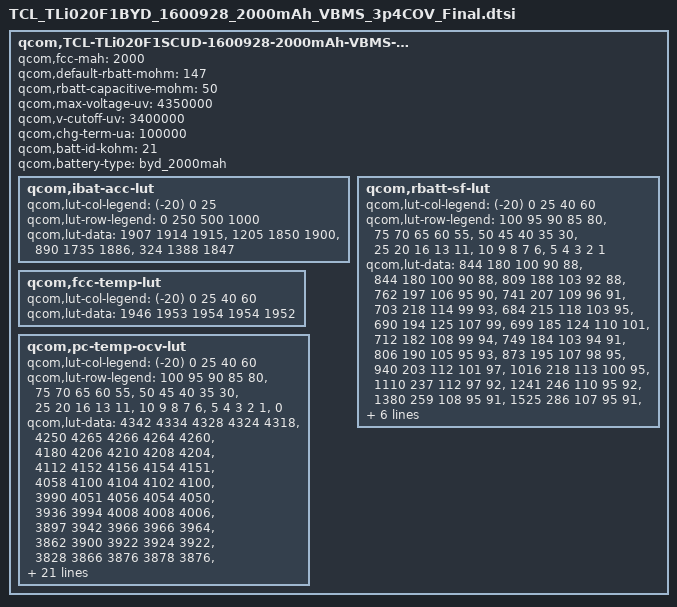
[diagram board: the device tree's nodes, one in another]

 qcom,TCL-TLi020F1SCUD-1600928-2000mAh-VBMS-data {
	qcom,fcc-mah = <2000>;
	qcom,default-rbatt-mohm = <147>;
	qcom,rbatt-capacitive-mohm = <50>;
	qcom,max-voltage-uv = <4350000>;
	qcom,v-cutoff-uv = <3400000>;
	qcom,chg-term-ua = <100000>;
	qcom,batt-id-kohm = <21>;
	qcom,battery-type = "byd_2000mah";
	qcom,ibat-acc-lut {
		qcom,lut-col-legend = <(-20) 0 25>;
		qcom,lut-row-legend = <0 250 500 1000>;
		qcom,lut-data = <1907 1914 1915>,
				<1205 1850 1900>,
				<890 1735 1886>,
				<324 1388 1847>;
	};

	qcom,rbatt-sf-lut {
		qcom,lut-col-legend = <(-20) 0 25 40 60>;
		qcom,lut-row-legend = <100 95 90 85 80>,
				<75 70 65 60 55>,
				<50 45 40 35 30>,
				<25 20 16 13 11>,
				<10 9 8 7 6>,
				<5 4 3 2 1>;
		qcom,lut-data = <844 180 100 90 88>,
				<844 180 100 90 88>,
				<809 188 103 92 88>,
				<762 197 106 95 90>,
				<741 207 109 96 91>,
				<703 218 114 99 93>,
				<684 215 118 103 95>,
				<690 194 125 107 99>,
				<699 185 124 110 101>,
				<712 182 108 99 94>,
				<749 184 103 94 91>,
				<806 190 105 95 93>,
				<873 195 107 98 95>,
				<940 203 112 101 97>,
				<1016 218 113 100 95>,
				<1110 237 112 97 92>,
				<1241 246 110 95 92>,
				<1380 259 108 95 91>,
				<1525 286 107 95 91>,
				<1679 321 110 97 93>,
				<1790 343 113 99 94>,
				<1906 363 116 101 95>,
				<1876 371 118 102 96>,
				<1953 397 121 103 97>,
				<2356 442 124 103 96>,
				<2955 489 124 101 94>,
				<3872 558 124 101 96>,
				<5648 682 135 107 100>,
				<9659 990 154 118 108>,
				<23470 9497 410 197 146>;
	};

	qcom,fcc-temp-lut {
		qcom,lut-col-legend = <(-20) 0 25 40 60>;
		qcom,lut-data = <1946 1953 1954 1954 1952>;
	};

	qcom,pc-temp-ocv-lut {
		qcom,lut-col-legend = <(-20) 0 25 40 60>;
		qcom,lut-row-legend = <100 95 90 85 80>,
				<75 70 65 60 55>,
				<50 45 40 35 30>,
				<25 20 16 13 11>,
				<10 9 8 7 6>,
				<5 4 3 2 1>,
				<0>;
		qcom,lut-data = <4342 4334 4328 4324 4318>,
				<4250 4265 4266 4264 4260>,
				<4180 4206 4210 4208 4204>,
				<4112 4152 4156 4154 4151>,
				<4058 4100 4104 4102 4100>,
				<3990 4051 4056 4054 4050>,
				<3936 3994 4008 4008 4006>,
				<3897 3942 3966 3966 3964>,
				<3862 3900 3922 3924 3922>,
				<3828 3866 3876 3878 3876>,
				<3802 3838 3844 3844 3844>,
				<3782 3816 3820 3820 3819>,
				<3764 3796 3800 3801 3799>,
				<3749 3782 3784 3784 3781>,
				<3735 3772 3772 3768 3760>,
				<3722 3758 3758 3749 3736>,
				<3712 3732 3734 3726 3712>,
				<3700 3710 3707 3698 3686>,
				<3688 3698 3688 3680 3668>,
				<3672 3692 3683 3676 3664>,
				<3664 3688 3682 3674 3662>,
				<3652 3684 3680 3672 3660>,
				<3638 3680 3678 3670 3658>,
				<3620 3673 3674 3666 3653>,
				<3598 3660 3664 3654 3640>,
				<3570 3635 3638 3626 3606>,
				<3530 3589 3590 3578 3559>,
				<3474 3524 3527 3516 3496>,
				<3386 3432 3442 3430 3411>,
				<3246 3289 3312 3302 3283>,
				<3000 3000 3000 3000 3000>;
	};
};
